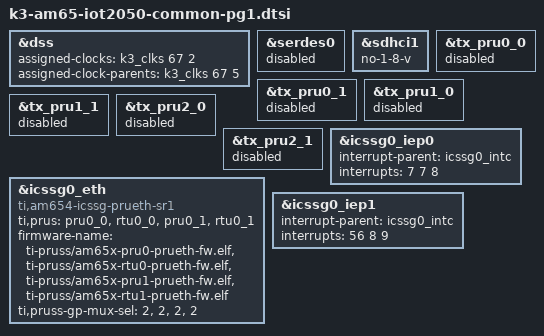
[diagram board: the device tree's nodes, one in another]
// SPDX-License-Identifier: GPL-2.0
/*
 * Copyright (c) Siemens AG, 2021
 *
 * Authors:
 *   Jan Kiszka <jan.kiszka@siemens.com>
 *
 * Common bits of the IOT2050 Basic and Advanced variants, PG1
 */

&dss {
	assigned-clocks = <&k3_clks 67 2>;
	assigned-clock-parents = <&k3_clks 67 5>;
};

&serdes0 {
	status = "disabled";
};

&sdhci1 {
	no-1-8-v;
};

&tx_pru0_0 {
	status = "disabled";
};

&tx_pru0_1 {
	status = "disabled";
};

&tx_pru1_0 {
	status = "disabled";
};

&tx_pru1_1 {
	status = "disabled";
};

&tx_pru2_0 {
	status = "disabled";
};

&tx_pru2_1 {
	status = "disabled";
};

&icssg0_eth {
	compatible = "ti,am654-icssg-prueth-sr1";
	ti,prus = <&pru0_0>, <&rtu0_0>, <&pru0_1>, <&rtu0_1>;
	firmware-name = "ti-pruss/am65x-pru0-prueth-fw.elf",
			"ti-pruss/am65x-rtu0-prueth-fw.elf",
			"ti-pruss/am65x-pru1-prueth-fw.elf",
			"ti-pruss/am65x-rtu1-prueth-fw.elf";
	ti,pruss-gp-mux-sel = <2>,      /* MII mode */
			      <2>,
			      <2>,      /* MII mode */
			      <2>;
};

&icssg0_iep0 {
	interrupt-parent = <&icssg0_intc>;
	interrupts = <7 7 8>;
	interrupt-names = "iep_cap_cmp";
};

&icssg0_iep1 {
	interrupt-parent = <&icssg0_intc>;
	interrupts = <56 8 9>;
	interrupt-names = "iep_cap_cmp";
};
